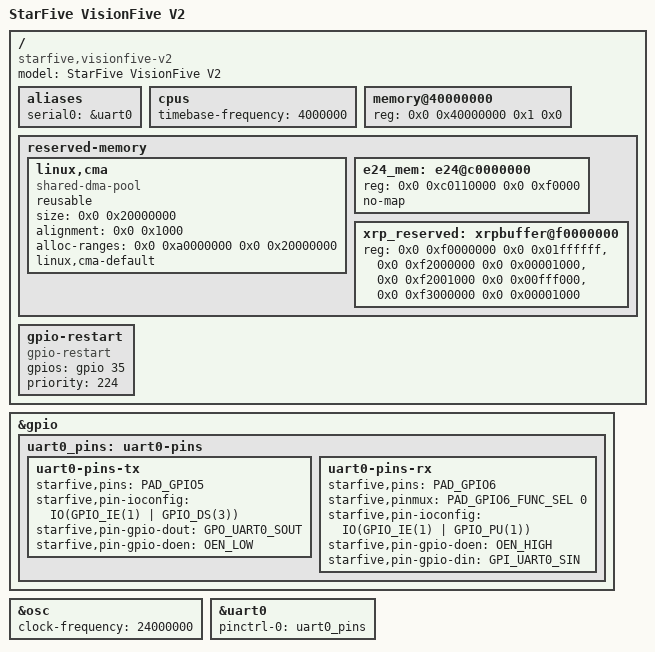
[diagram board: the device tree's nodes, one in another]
// SPDX-License-Identifier: GPL-2.0 OR MIT
/*
 * Copyright (C) 2022 StarFive Technology Co., Ltd.
 * Copyright (C) 2022 Emil Renner Berthing <kernel@esmil.dk>
 */

/dts-v1/;
#include "jh7110.dtsi"
#include <dt-bindings/gpio/gpio.h>
#include <dt-bindings/pinctrl/pinctrl-starfive-jh7110.h>

/ {
	model = "StarFive VisionFive V2";
	compatible = "starfive,visionfive-v2", "starfive,jh7110";

	aliases {
		serial0 = &uart0;
	};

	cpus {
		timebase-frequency = <4000000>;
	};

	memory@40000000 {
		device_type = "memory";
		reg = <0x0 0x40000000 0x1 0x0>;
	};

	reserved-memory {
		#address-cells = <2>;
		#size-cells = <2>;
		ranges;

		linux,cma {
			compatible = "shared-dma-pool";
			reusable;
			size = <0x0 0x20000000>;
			alignment = <0x0 0x1000>;
			alloc-ranges = <0x0 0xa0000000 0x0 0x20000000>;
			linux,cma-default;
		};

		e24_mem: e24@c0000000 {
			reg = <0x0 0xc0110000 0x0 0xf0000>;
			no-map;
		};

		xrp_reserved: xrpbuffer@f0000000 {
			reg = <0x0 0xf0000000 0x0 0x01ffffff>,
			      <0x0 0xf2000000 0x0 0x00001000>,
			      <0x0 0xf2001000 0x0 0x00fff000>,
			      <0x0 0xf3000000 0x0 0x00001000>;
		};

	};

	gpio-restart {
		compatible = "gpio-restart";
		gpios = <&gpio 35 GPIO_ACTIVE_HIGH>;
		priority = <224>;
	};
};

&gpio {
	uart0_pins: uart0-pins {
		uart0-pins-tx {
			starfive,pins = <PAD_GPIO5>;
			starfive,pin-ioconfig = <IO(GPIO_IE(1) | GPIO_DS(3))>;
			starfive,pin-gpio-dout = <GPO_UART0_SOUT>;
			starfive,pin-gpio-doen = <OEN_LOW>;
		};

		uart0-pins-rx {
			starfive,pins = <PAD_GPIO6>;
			starfive,pinmux = <PAD_GPIO6_FUNC_SEL 0>;
			starfive,pin-ioconfig = <IO(GPIO_IE(1) | GPIO_PU(1))>;
			starfive,pin-gpio-doen = <OEN_HIGH>;
			starfive,pin-gpio-din =  <GPI_UART0_SIN>;
		};
	};
};

&osc {
	clock-frequency = <24000000>;
};

&uart0 {
	pinctrl-names = "default";
	pinctrl-0 = <&uart0_pins>;
	status = "okay";
};
